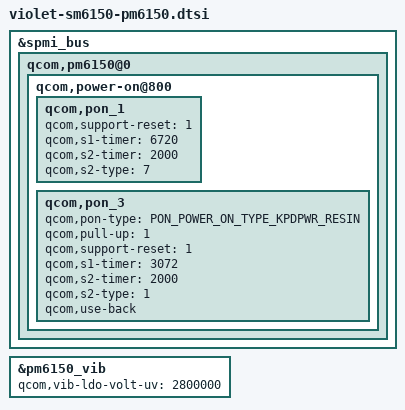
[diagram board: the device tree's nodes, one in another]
/*
 * Copyright (C) 2020 The LineageOS Project
 *
 * this file is for attribution only of violet
 * And public attribution of Xiaomi platforms (like F7B and so)
 */

#include <dt-bindings/input/qcom,qpnp-power-on.h>

&spmi_bus {
    qcom,pm6150@0 {
        qcom,power-on@800 {
            qcom,pon_1 {
                qcom,support-reset = <1>;
                qcom,s1-timer = <6720>;
                qcom,s2-timer = <2000>;
                qcom,s2-type = <7>;    
            };

            qcom,pon_3 {
                qcom,pon-type = <PON_POWER_ON_TYPE_KPDPWR_RESIN>;
                qcom,pull-up = <1>;
                qcom,support-reset = <1>;
                qcom,s1-timer = <3072>;
                qcom,s2-timer = <2000>;
                qcom,s2-type = <1>;
                qcom,use-back;
            };
        };
    };
};

&pm6150_vib {
    qcom,vib-ldo-volt-uv = <2800000>;
};
